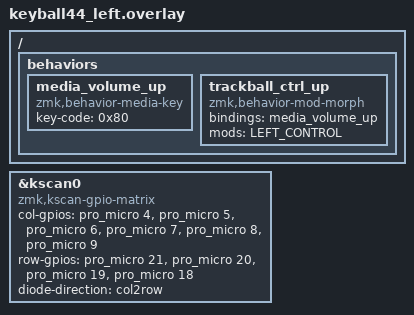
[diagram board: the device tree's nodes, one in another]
/*
 * Copyright (c) 2020 ZMK Contributors
 *
 * SPDX-License-Identifier: MIT
 */

#include "keyball44.dtsi"

&kscan0 {
    compatible = "zmk,kscan-gpio-matrix"; // Ensure compatibility is explicitly defined
    col-gpios = <&pro_micro 4 GPIO_ACTIVE_HIGH>,
                <&pro_micro 5 GPIO_ACTIVE_HIGH>,
                <&pro_micro 6 GPIO_ACTIVE_HIGH>,
                <&pro_micro 7 GPIO_ACTIVE_HIGH>,
                <&pro_micro 8 GPIO_ACTIVE_HIGH>,
                <&pro_micro 9 GPIO_ACTIVE_HIGH>;
    row-gpios = <&pro_micro 21 GPIO_ACTIVE_HIGH>,
                <&pro_micro 20 GPIO_ACTIVE_HIGH>,
                <&pro_micro 19 GPIO_ACTIVE_HIGH>,
                <&pro_micro 18 GPIO_ACTIVE_HIGH>;
    diode-direction = "col2row"; // Ensure diode direction is defined
};

// Define the behaviors node
/ {
    behaviors {
        media_volume_up {
            compatible = "zmk,behavior-media-key";
            key-code = <0x80>; // HID code for volume up
            #binding-cells = <0>;
        };

        trackball_ctrl_up {
            compatible = "zmk,behavior-mod-morph";
            #binding-cells = <2>;
            bindings = <&media_volume_up>;
            mods = <LEFT_CONTROL>;
        };
    };
};
